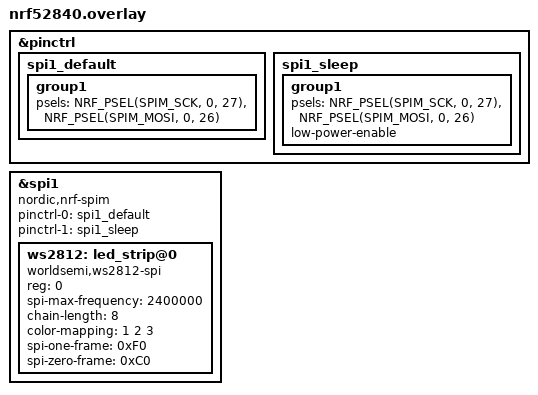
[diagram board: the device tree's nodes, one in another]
&pinctrl {
    spi1_default: spi1_default {
        group1 {
            psels = <NRF_PSEL(SPIM_SCK, 0, 27)>,
                    <NRF_PSEL(SPIM_MOSI, 0, 26)>;
        };
    };

    spi1_sleep: spi1_sleep {
        group1 {
            psels = <NRF_PSEL(SPIM_SCK, 0, 27)>,
                    <NRF_PSEL(SPIM_MOSI, 0, 26)>;
            low-power-enable;
        };
    };
};

&spi1 {
    compatible = "nordic,nrf-spim";
    status = "okay";

    pinctrl-0 = <&spi1_default>;
    pinctrl-1 = <&spi1_sleep>;
    pinctrl-names = "default", "sleep";

    ws2812: led_strip@0 {
        compatible = "worldsemi,ws2812-spi";
        reg = <0>;

        spi-max-frequency = <2400000>;

        chain-length = <8>;
        color-mapping = <1 2 3>;

        spi-one-frame = <0xF0>;
        spi-zero-frame = <0xC0>;
    };
};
